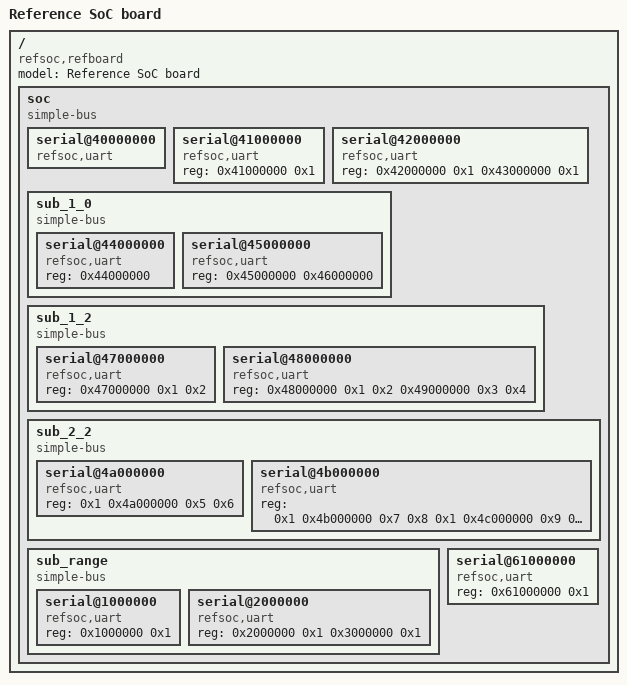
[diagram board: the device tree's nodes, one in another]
/dts-v1/;

/ {
	#address-cells = <0x1>;
	#size-cells = <0x1>;
	model = "Reference SoC board";
	compatible = "refsoc,refboard";

	soc {
		#address-cells = <0x1>;
		#size-cells = <0x1>;
		compatible = "simple-bus";
		ranges;

		/* no reg */
		serial@40000000 {
			compatible = "refsoc,uart";
		};

		/* one reg */
		serial@41000000 {
			compatible = "refsoc,uart";
			reg = <0x41000000 0x1>;
		};

		/* two reg */
		serial@42000000 {
			compatible = "refsoc,uart";
			reg = <0x42000000 0x1 0x43000000 0x1>;
		};

		/* Nodes are 1 addr cell, and 0 size cells (like i2c) */
		sub_1_0 {
			#address-cells = <0x1>;
			#size-cells = <0x0>;
			compatible = "simple-bus";
			ranges;

			/* one address */
			serial@44000000 {
				compatible = "refsoc,uart";
				reg = <0x44000000>;
			};

			/* two addresses */
			serial@45000000 {
				compatible = "refsoc,uart";
				reg = <0x45000000 0x46000000>;
			};
		};

		/* Nodes are 1 addr cell, and 2 size cells */
		sub_1_2 {
			#address-cells = <0x1>;
			#size-cells = <0x2>;
			compatible = "simple-bus";
			ranges;

			/* one address */
			serial@47000000 {
				compatible = "refsoc,uart";
				reg = <0x47000000 0x1 0x2>;
			};

			/* two addresses */
			serial@48000000 {
				compatible = "refsoc,uart";
				reg = <0x48000000 0x1 0x2 0x49000000 0x3 0x4>;
			};
		};

		/* Nodes are 2 addr cell, and 2 size cells (64-bit system) */
		sub_2_2 {
			#address-cells = <0x2>;
			#size-cells = <0x2>;
			compatible = "simple-bus";
			ranges;

			/* one address */
			serial@4a000000 {
				compatible = "refsoc,uart";
				reg = <0x1 0x4a000000 0x5 0x6>;
			};

			/* two addresses */
			serial@4b000000 {
				compatible = "refsoc,uart";
				reg = <0x1 0x4b000000 0x7 0x8 0x1 0x4c000000 0x9 0xa>;
			};
		};

		/* Go through an range translation */
		sub_range {
			#address-cells = <0x1>;
			#size-cells = <0x1>;
			compatible = "simple-bus";

			ranges = <0x0 0x50000000 0x10000000>;

			/* one reg */
			serial@1000000 {
				compatible = "refsoc,uart";
				reg = <0x1000000 0x1>;
			};

			/* two reg */
			serial@2000000 {
				compatible = "refsoc,uart";
				reg = <0x2000000 0x1 0x3000000 0x1>;
			};
		};

		/* one reg - with regnames */
		serial@61000000 {
			compatible = "refsoc,uart";
			reg = <0x61000000 0x1>;
			reg-names = "reg1";
		};

		/* two reg - with regnames */
		serial@42000000 {
			compatible = "refsoc,uart";
			reg = <0x42000000 0x1 0x43000000 0x1>;
			reg-names = "reg1", "reg2";
		};

		/* two reg - with regnames only for one */
		serial@42000000 {
			compatible = "refsoc,uart";
			reg = <0x42000000 0x1 0x43000000 0x1>;
			reg-names = "reg1";
		};
	};
};
